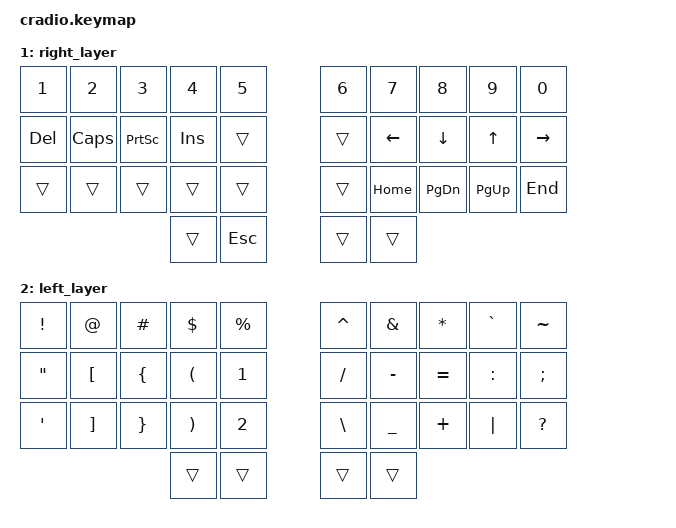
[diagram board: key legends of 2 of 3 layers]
// Copyright (c) 2022 The ZMK Contributors
// SPDX-License-Identifier: MIT

#include <behaviors.dtsi>
#include <dt-bindings/zmk/keys.h>
#include <dt-bindings/zmk/bt.h>
#include <dt-bindings/zmk/outputs.h>

// Home row mods macro
#define HRML(k2,k3,k4) &ht LALT k2  &ht LCTRL k3  &ht LGUI k4
#define HRMR(k1,k2,k3) &ht RGUI k1  &ht RCTRL k2  &ht RALT k3

#define MAC 0
#define RIG 1
#define LEF 2
/ {
    behaviors {
        ht: hold_tap {
            label = "hold_tap";
            compatible = "zmk,behavior-hold-tap";
            #binding-cells = <2>;
            flavor = "tap-preferred";
            tapping-term-ms = <220>;
            quick-tap-ms = <150>;
            global-quick-tap;
            bindings = <&kp>, <&kp>;
        };
    };

    keymap {
        compatible = "zmk,keymap";
        default_layer {
            bindings = <
        //╭──────────┬──────────┬──────────┬──────────┬──────────╮   ╭──────────┬──────────┬──────────┬──────────┬──────────╮
        //│  Q       │  W       │  E       │  R       │  T       │   │  Y       │  U       │  I       │  O       │  P       │
            &kp Q      &kp W      &kp E      &kp R      &kp T          &kp Y      &kp U      &kp I      &kp O      &kp P
        //├──────────┼──────────┼──────────┼──────────┼──────────┤   ├──────────┼──────────┼──────────┼──────────┼──────────┤
        //│  A       │  S       │  D       │  F       │  G       │   │  H       │  J       │  K       │  L       │BACKSPACE │
            &kp A     HRML(S,         D,         F)     &kp G          &kp H      HRMR(J,        K,           L)   &kp BSPC
        //├──────────┼──────────┼──────────┼──────────┼──────────┤   ├──────────┼──────────┼──────────┼──────────┼──────────┤
        //│  Z       │  X       │  C       │  V       │  B       │   │  N       │  M       │ ,        │ .        │ RETURN   │
            &kp Z      &kp X      &kp C      &kp V      &kp B          &kp N      &kp M      &kp COMMA  &kp DOT   &kp RETURN
        //╰──────────┴──────────┴──────────┼──────────┼──────────┤   ├──────────┼──────────┼──────────┴──────────┴──────────╯
                                           &lt LEF TAB  &kp LSHIFT    &kp SPACE  &lt RIG ESC
        //                                 ╰──────────┴──────────╯   ╰──────────┴──────────╯
            >;
        };


        right_layer {
            bindings = <
        //╭──────────┬──────────┬──────────┬──────────┬──────────╮   ╭──────────┬──────────┬──────────┬──────────┬──────────╮
        //│ 1        │  2       │  3       │  4       │  5       │   │ 6        │ 7        │ 8        │ 9        │   0      │
            &kp N1    &kp N2     &kp N3     &kp N4     &kp N5          &kp N6     &kp N7     &kp N8     &kp N9      &kp N0
        //├──────────┼──────────┼──────────┼──────────┼──────────┤   ├──────────┼──────────┼──────────┼──────────┼──────────┤
        //│ DELETE   │ CapsLock │ PrintSc  │  INSERT  │          |   |          │ LEFT     │ DOWN     │ UP       │ RIGHT    │
            &kp DEL   &kp CAPS   &kp PSCRN  &kp INS     &trans          &trans    &kp LEFT   &kp DOWN   &kp UP   &kp RIGHT 
        //├──────────┼──────────┼──────────┼──────────┼──────────┤   ├──────────┼──────────┼──────────┼──────────┼──────────┤
        //│          │          │          │          │          │   │          │ HOME     │ PAGE DN  │ PAGE UP  │ END      │
            &trans    &trans     &trans     &trans      &trans           &trans    &kp HOME  &kp PG_DN  &kp PG_UP  &kp END 
        //╰──────────┴──────────┴──────────┼──────────┼──────────┤   ├──────────┼──────────┼──────────┴──────────┴──────────╯
                                             &trans     &kp ESC        &trans     &trans
        //                                 ╰──────────┴──────────╯   ╰──────────┴──────────╯
            >;
        };

        left_layer {
            bindings = <
        //╭──────────┬──────────┬──────────┬──────────┬──────────╮   ╭──────────┬──────────┬──────────┬──────────┬──────────╮
        //│  !       │  @       │  #       │  $       │  %       │   │  ^       │  &       │  *       │  `       │  ~       │
            &kp EXCL   &kp AT     &kp HASH   &kp DLLR   &kp PRCNT      &kp CARET  &kp AMPS   &kp ASTRK  &kp GRAVE   &kp TILDE
        //├──────────┼──────────┼──────────┼──────────┼──────────┤   ├──────────┼──────────┼──────────┼──────────┼──────────┤
        //│  "       │  [       │  {       │  (       │    1     │   │   /      │  -       │  =       │     :    │  ;       │
            &kp DQT  &kp LBKT   &kp LBRC   &kp LPAR       &kp N1      &kp FSLH   &kp MINUS  &kp EQUAL  &kp COLON   &kp SEMI
        //├──────────┼──────────┼──────────┼──────────┼──────────┤   ├──────────┼──────────┼──────────┼──────────┼──────────┤
        //│  '       │  ]       │  }       │  )       │    2     │   │    \     │  _       │  +       │  │       │   ?      │
            &kp SQT     &kp RBKT   &kp RBRC   &kp RPAR   &kp N2        &kp BSLH   &kp UNDER  &kp PLUS   &kp PIPE  &kp QMARK
        //╰──────────┴──────────┴──────────┼──────────┼──────────┤   ├──────────┼──────────┼──────────┴──────────┴──────────╯
                                             &trans     &trans         &trans     &trans
        //                                 ╰──────────┴──────────╯   ╰──────────┴──────────╯
            >;
        };

    };
};
